# slm32x030 register map
Vendor: Keil; File version: 1.0.1
Arm 32-bit Cortex-M0+ Microcontroller based device, CPU clock up to 64 MHz.
CPU: CM0 r2p1, little endian, no MPU, no FPU, 4 interrupt priority bits
Registers are 32-bit, read-write, reset 0x0 unless marked. A register's access mark holds for its fields unless they carry their own. Offsets are from the block's base; lines under a group give offsets from that group; [hi:lo] are bit positions; {n}, {i} and the like mark numbered series; 'fields as' and 'values as' point back to an identical list; <NAME> marks a mode.

## Memory map
0x40000400 TIM3 size 0x400 — timer(TIMX)
0x40001000 TIM6 size 0x400 — timer(TIMX)
0x40001400 TIM7 size 0x400 — timer(TIMX)
0x40002000 TIM14 size 0x400 — timer(TIMX)
0x40002800 RTC size 0x400 — Real time clock RTC
0x40002C00 WWDG size 0x400 — Window Watchdog(WWDG)
0x40003000 IWDG size 0x400 — Independent watchdog(IWDG)
0x40003800 SPI2 size 0x400 — Serial Peripheral Interface(SPI)
0x40004400 USART2 size 0x400 — Universal synchronous asynchronous transceiver(USART)
0x40005000 LPUART size 0x400 — Low power general-purpose asynchronous transceiver(LPUART)
0x40005400 I2C1 size 0x400 — I2C interface
0x40005800 I2C2 size 0x400 — I2C interface
0x40005C00 VC size 0x400 — voltage comparator(VC)
0x40007000 PMU size 0x400
0x40010000 SYSCFG size 0x400 — system configuration(SYSCFG)
0x40010400 EXTI size 0x400 — Interruptions and Events(IEMU)
0x40012400 ADC size 0x400 — analog to digital(ADC)
0x40012800 AWK size 0x400 — Self-wake timer(AWK)
0x40012C00 TIM1 size 0x400 — timer(TIMX)
0x40013000 SPI1 size 0x400 — Serial Peripheral Interface(SPI)
0x40013800 USART1 size 0x400 — Universal synchronous asynchronous transceiver(USART)
0x40013C00 LPTIM size 0x400 — Low power timer(LPTIM)
0x40014000 TIM15 size 0x400 — timer(TIMX)
0x40014400 TIM16 size 0x400 — timer(TIMX)
0x40014800 TIM17 size 0x400 — timer(TIMX)
0x40015000 LVD size 0x400 — Low voltage detector(LVD)
0x40015400 BEEP size 0x400 — buzzer(BEEP)
0x40015800 DBGMCU size 0x400 — Debugging support(DBGMCU)
0x40020000 DMA size 0x400 — DMA(DMA)
0x40021000 RCMU size 0x400
0x40022000 FLASH size 0x400
0x40022800 SRAM size 0x400 — control(SRAM)
0x40023000 CRC size 0x400
0x40023400 TRNG size 0x400 — random number generator(TRNG)
0x40023800 AES size 0x400 — Hardware accelerator(AES)
0x48000000 GPIOA size 0x400 — Io function
0x48000400 GPIOB size 0x400
0x48000800 GPIOC size 0x400
0x48000C00 GPIOD size 0x400

## Interrupts
0 WWDG — Window timer interrupt
2 RTC — Real time clock Interrupt
3 FLASH — Flash Interrupt
4 RCMU — 1
5 EXTI0_1 (EXTI) — External event line 0 and 1 mixed interrupt
6 EXTI2_3 (EXTI) — External event line 2 and 3 mixed interrupt
7 EXTI4_15 (EXTI) — External event line 4 and 15 mixed interrupt
8 AES — AES Interrupt
9 DMA — DMA Interrupt(six CH)
10 AWKTIM (AWK) — AWKTIM Interrupt
12 ADC — ADC Interrupt
13 TIM1_BRK_UP_TRG_COM (TIM1) — TIM1 Mixed interrupt
14 TIM1_CC (TIM1) — TIM1 Capture Compare Interrupt
15 SRAM — SRAM Interrupt
16 TIM3 — TIM3 Bureau interruption
17 TIM6 — TIM6 Interrupt
18 TIM7 — TIM7 Interrupt
19 TIM14 — TIM14 Interrupt
20 TIM15 — TIM15 Interrupt
21 TIM16 — TIM16 Interrupt
22 TIM17 — TIM17 Interrupt
23 I2C1 — I2C1 Interrupt
24 I2C2 — I2C2 Interrupt
25 SPI1 — SPI1 Interrupt
26 SPI2 — SPI2 Interrupt
27 USART1 — USART1 Interrupt
28 USART2 — USART2 Interrupt
29 LPUART — LPUART Interrupt
30 TRNG — TRNG Interrupt
31 VC — VC Interrupt

## FLASH
Base 0x40022000
0x00 ACR — FLASH_ACR
  [2:0] LATENCY — Later Add Description
0x04 KEYR access not given — FLASH_KEYR
  [31:0] KEYR — Later Add Description
0x08 OPTKEYR access not given — FLASH_OPTKEYR
  [31:0] OPTKEYR — Later Add Description
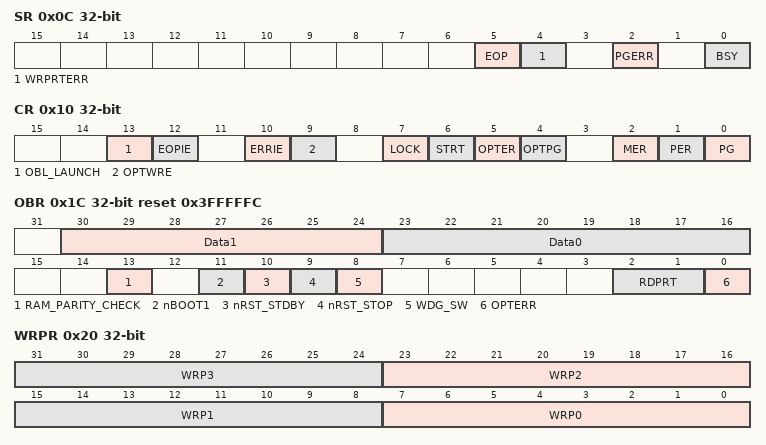
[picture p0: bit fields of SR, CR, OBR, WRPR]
0x0C SR access not given — FLASH_SR
  [5] EOP rw — Later Add Description
  [4] WRPRTERR rw — Later Add Description
  [2] PGERR rw — Later Add Description
  [0] BSY — Later Add Description
0x10 CR — FLASH_CR
  [13] OBL_LAUNCH — Later Add Description
  [12] EOPIE — Later Add Description
  [10] ERRIE — Later Add Description
  [9] OPTWRE — Later Add Description
  [7] LOCK — Later Add Description
  [6] STRT — Later Add Description
  [5] OPTER — Later Add Description
  [4] OPTPG — Later Add Description
  [2] MER — Later Add Description
  [1] PER — Later Add Description
  [0] PG — Later Add Description
0x14 AR access not given — FLASH_AR
  [31:0] FAR — Later Add Description
0x1C OBR access not given reset 0x3FFFFFC — FLASH_OBR
  [30:24] Data1 — Later Add Description
  [23:16] Data0 — Later Add Description
  [13] RAM_PARITY_CHECK — Later Add Description
  [11] nBOOT1 — Later Add Description
  [10] nRST_STDBY — Later Add Description
  [9] nRST_STOP — Later Add Description
  [8] WDG_SW — Later Add Description
  [2:1] RDPRT — Later Add Description
  [0] OPTERR — Later Add Description
0x20 WRPR access not given — FLASH_WRPR
  [8n+7:8n] WRP{n} (n=0..3) — Later Add Description
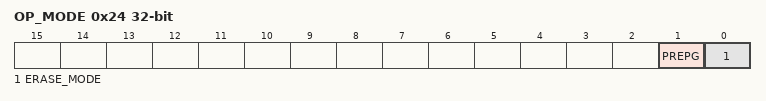
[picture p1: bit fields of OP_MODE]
0x24 OP_MODE — FLASH_OP_MODE
  [1] PREPG — Later Add Description
  [0] ERASE_MODE — Later Add Description
